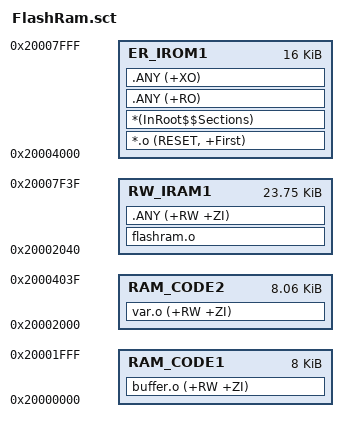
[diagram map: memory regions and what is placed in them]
; *************************************************************
; *** Scatter-Loading Description File generated by uVision ***
; *************************************************************

LR_IROM1 0x20004000 0x00004000  {    ; load region size_region
  ER_IROM1 0x20004000 0x00004000  {  ; load address = execution address
   *.o (RESET, +First)
   *(InRoot$$Sections)
   .ANY (+RO)
   .ANY (+XO)
  }
  RAM_CODE1 0x20000000 0x00002000  {  ; RW data
   buffer.o (+RW +ZI)
  }
  RAM_CODE2 0x20002000 0x00002040  {  ; RW data
   var.o (+RW +ZI)
  }
  RW_IRAM1 0x20002040 (0x20008000 - 0x20002100)  {  ; RW data
   flashram.o
   .ANY (+RW +ZI)
  }
}

